# haltium_sysctrl register map
Vendor: Nordic Semiconductor; Series: nRFHaltium; File version: 1
Registers are 32-bit, read-write, reset 0x0 unless marked. A register's access mark holds for its fields unless they carry their own. Offsets are from the block's base; [hi:lo] are bit positions; lines under a group give offsets from that group; 'fields as' and 'values as' point back to an identical list.

## VREGAO1V8_S — VREGAO1V8
Base 0x5F962000
0x400 STATUS ro — Voltage regulator status
  [1:0] MODE — Current voltage regulator mode
    0=High power mode; 1=Low power refresh mode; 2=Ultra-low power refresh mode; 3=Low Power Refresh Differential 5v0 and 1v8
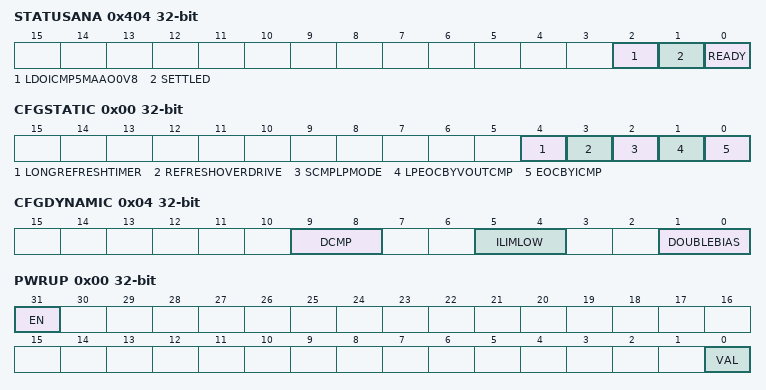
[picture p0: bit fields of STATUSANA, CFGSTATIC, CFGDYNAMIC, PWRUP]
0x404 STATUSANA ro — Status of analog module output signals
  [2] LDOICMP5MAAO0V8 — Current value of the LDO_ICMP_5MA_AO_0V8 signal from the analog module
  [1] SETTLED — Current value of the SETTLED signal from the analog module
  [0] READY — Current value of the READY signal from the analog module
0x410 CONFIG group — Unspecified
  0x00 CFGSTATIC — VREGAO1V8 static CFG configuration
    [all] fields
      0=Disabled (Configuration disabled); 1=Enabled (Configuration enabled)
    [4] LONGREFRESHTIMER — Configuration for Long refresh timer
    [3] REFRESHOVERDRIVE — Configuration for 10mV refresh overdirve
    [2] SCMPLPMODE — Configuration for SCMP in LP mode
    [1] LPEOCBYVOUTCMP — Configuration for LP EOC BY VOUTCMP
    [0] EOCBYICMP — Configuration for EOC by ICMP
  0x04 CFGDYNAMIC — VREGAO1V8 dynamic CFG configuration
    [all] fields
      0=Automatically handled by the MMI; 1=Disabled (Configuration disabled); 2=Enabled (Configuration enabled)
    [9:8] DCMP — Configuration for DCMP
    [5:4] ILIMLOW — Current limit low configuration for the voltage regulator
    [1:0] DOUBLEBIAS — Double bias current configuration for the voltage regulator
0x440 TRIM group — Unspecified
  0x00 VREF — Internal voltage reference trimming
    [6:0] VAL — Voltage reference trimming value
  0x04 HIGHPOWER — High power mode output voltage offset trimming
    [2:0] VAL — Voltage offset trimming value
  0x08 LOWPOWER — Low power mode output voltage offset trimming
    [2:0] VAL — Voltage offset trimming value.
0x480 MIRROR reset 0x1 — Enable LOCK for mirrored registers
  [0] LOCK — Lock for mirrored registers
    0=Disabled (Lock disabled); 1=Enabled (Lock enabled)
0x484 VOUT reset 0x4 — Output voltage programming
  [2:0] VAL — Output voltage value
0x488 PWRUPCTRL — Power up control
  [1:0] CTRL
    0=Automatically handled by the MMI; 1=PowerUp; 2=PowerDown
0x48C MODE — Voltage regulator mode
  [2:0] MODE
    0=Automatically handled by the MMI; 1=High power mode; 2=Low power refresh mode; 3=Ultra-low power refresh mode; 4=Low Power Refresh Differential 5v0 and 1v8
0x500 OVERRIDE group — Unspecified
  0x00 PWRUP — Override the PWRUP signal to the analog module
    [31] EN — Enable the override
      0=Disabled (Override is disabled); 1=Enabled (Override is enabled)
    [0] VAL — Override value for the signal
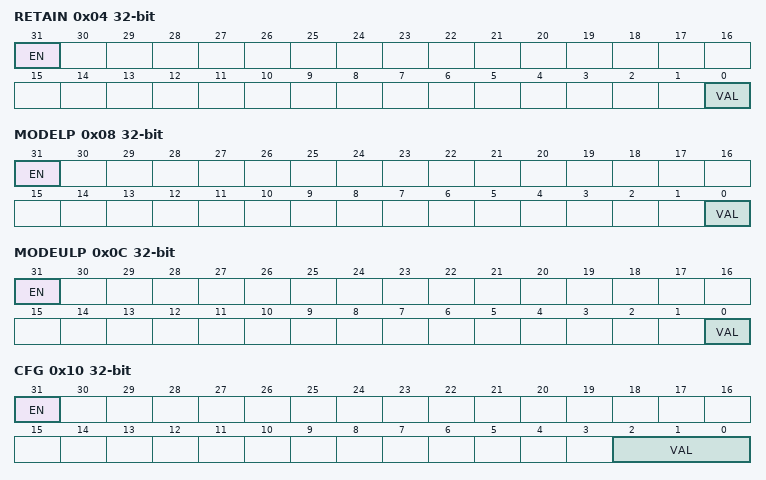
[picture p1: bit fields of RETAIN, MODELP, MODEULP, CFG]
  0x04 RETAIN — Override the RETAIN signal to the analog module
    fields as OVERRIDE.PWRUP
  0x08 MODELP — Override the MODE LP signal to the analog module
    fields as OVERRIDE.PWRUP
  0x0C MODEULP — Override the MODE ULP signal to the analog module
    fields as OVERRIDE.PWRUP
  0x10 CFG — Override the dynamic CFG[2:0] signal to the analog module
    [31] EN — Enable the override
      values as OVERRIDE.PWRUP.EN
    [2:0] VAL — Override value for the signal
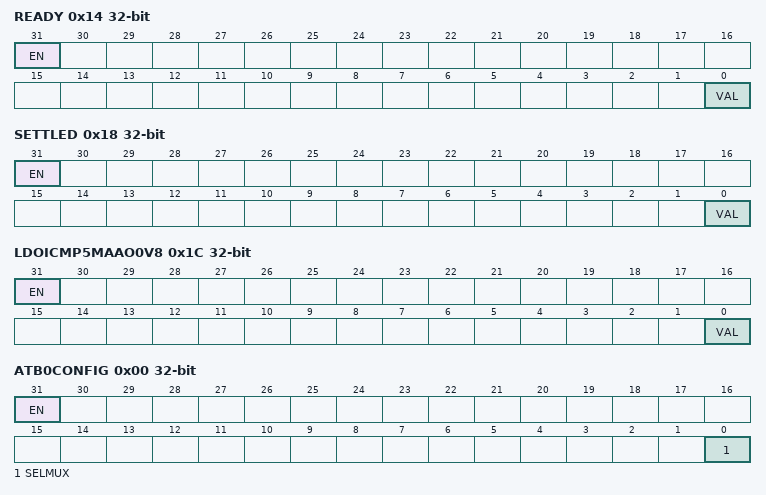
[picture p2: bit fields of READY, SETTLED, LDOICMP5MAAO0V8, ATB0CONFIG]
  0x14 READY — Override the READY signal from the analog module
    [31] EN — Enable the override
      values as OVERRIDE.PWRUP.EN
    [0] VAL — Current value of the signal
  0x18 SETTLED — Override the SETTLED signal from the analog module
    fields as OVERRIDE.READY
  0x1C LDOICMP5MAAO0V8 — Read the LDO_ICMP_5MA_AO_0V8 signal from the analog module
    fields as OVERRIDE.READY
0x600 DFT group — Unspecified
  0x00 ATB0CONFIG — Analog Test Bus 0 (ATB0) configuration
    [31] EN — Enable the analog test bus
      0=Disabled (Analog test bus is disabled); 1=Enabled (Analog test bus is enabled)
    [0] SELMUX — Select multiplexer for ATB0
      0=HiZ; 1=VSS
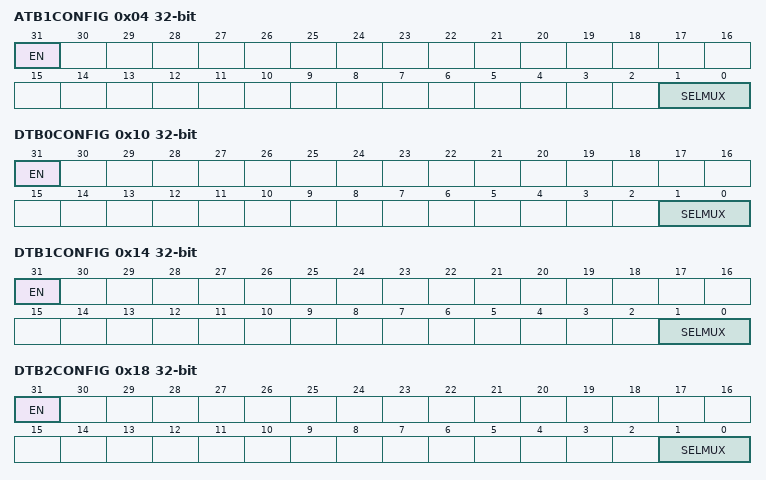
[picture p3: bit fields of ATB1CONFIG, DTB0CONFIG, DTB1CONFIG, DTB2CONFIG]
  0x04 ATB1CONFIG — Analog Test Bus 1 (ATB1) configuration
    [31] EN — Enable the analog test bus
      values as DFT.ATB0CONFIG.EN
    [1:0] SELMUX — Select multiplexer for ATB1
      0=HiZ; 1=VDDInt1v8; 2=BufferedVREF0V9; 3=BufferedVFB0V9
  0x10 DTB0CONFIG — Digital Test Bus 0 (DTB0) configuration
    [31] EN — Enable the digital test bus
      0=Disabled (Digital test bus is disabled); 1=Enabled (Digital test bus is enabled)
    [1:0] SELMUX — Select multiplexer for DTB0
      0=None selected; 1=ICMPForcePWRUP; 2=VSS; 3=Ready
  0x14 DTB1CONFIG — Digital Test Bus 1 (DTB1) configuration
    [31] EN — Enable the digital test bus
      values as DFT.DTB0CONFIG.EN
    [1:0] SELMUX — Select multiplexer for DTB1
      0=None selected; 1=CoreVrefOut; 2=Settled; 3=StateBit0
  0x18 DTB2CONFIG — Digital Test Bus 2 (DTB2) configuration
    [31] EN — Enable the digital test bus
      values as DFT.DTB0CONFIG.EN
    [1:0] SELMUX — Select multiplexer for DTB2
      0=None selected; 1=CoreBiasSettled1UA; 2=ModeInBit0; 3=StateBit1
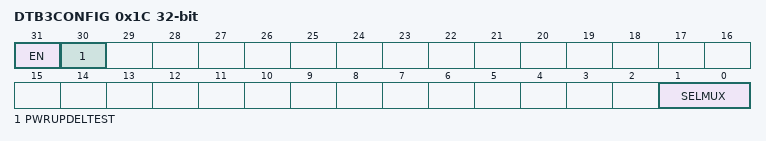
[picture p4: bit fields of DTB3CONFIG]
  0x1C DTB3CONFIG — Digital Test Bus 3 (DTB3) configuration
    [31] EN — Enable the digital test bus
      values as DFT.DTB0CONFIG.EN
    [30] PWRUPDELTEST — Enable the PWRUP delay test circuit
      0=Disabled (PWRUP delay test circuit is disabled); 1=Enabled (PWRUP delay test circuit is enabled)
    [1:0] SELMUX — Select multiplexer for DTB3
      0=None selected; 1=CoreBiasPWRUP1UA; 2=ModeInBit1; 3=StateBit2
  0x30 TCFG — Test mode configuration
    [1:0] MODE — Mode - TBD
